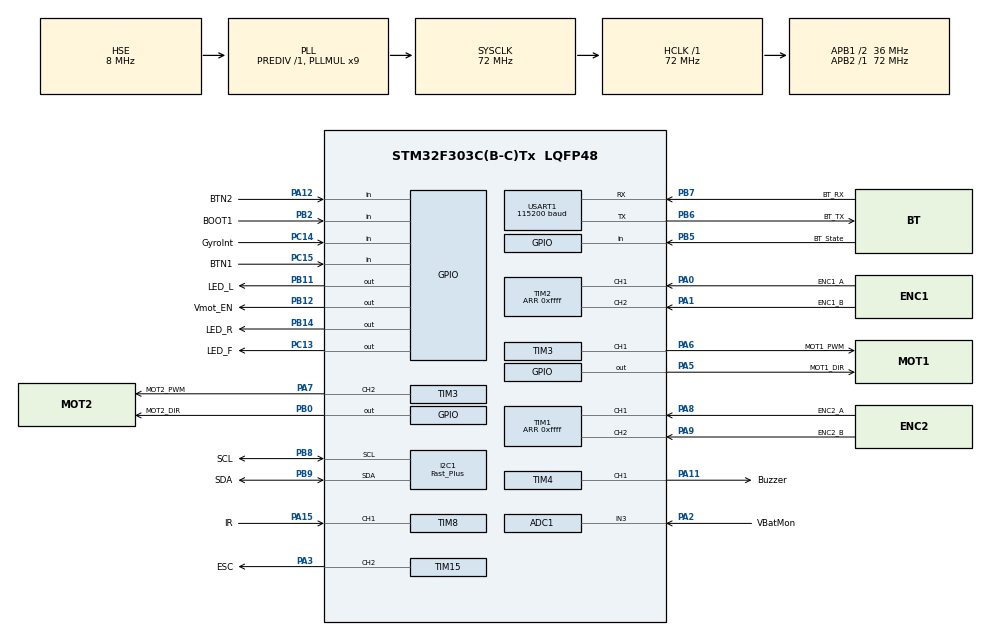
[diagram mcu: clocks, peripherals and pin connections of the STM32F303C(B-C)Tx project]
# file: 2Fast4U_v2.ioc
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ADC1.Channel-0\#ChannelRegularConversion=ADC_CHANNEL_3
ADC1.ClockPrescaler=ADC_CLOCK_ASYNC_DIV1
ADC1.ContinuousConvMode=DISABLE
ADC1.DMAContinuousRequests=DISABLE
ADC1.DataAlign=ADC_DATAALIGN_RIGHT
ADC1.DiscontinuousConvMode=DISABLE
ADC1.EOCSelection=ADC_EOC_SINGLE_CONV
ADC1.EnableAnalogWatchDog1=false
ADC1.EnableAnalogWatchDog2=false
ADC1.EnableAnalogWatchDog3=false
ADC1.EnableInjectedConversion=ENABLE
ADC1.EnableRegularConversion=ENABLE
ADC1.ExternalTrigConv=ADC_SOFTWARE_START
ADC1.ExternalTrigConvEdge=ADC_EXTERNALTRIGCONVEDGE_NONE
ADC1.InjNumberOfConversion=0
ADC1.LowPowerAutoWait=DISABLE
ADC1.NbrOfConversion=1
ADC1.NbrOfConversionFlag=1
ADC1.Offset-0\#ChannelRegularConversion=0
ADC1.OffsetNumber-0\#ChannelRegularConversion=ADC_OFFSET_NONE
ADC1.Overrun=ADC_OVR_DATA_OVERWRITTEN
ADC1.Rank-0\#ChannelRegularConversion=1
ADC1.Resolution=ADC_RESOLUTION_12B
ADC1.SamplingTime-0\#ChannelRegularConversion=ADC_SAMPLETIME_1CYCLE_5
ADC1.ScanConvMode=ADC_SCAN_DISABLE
ADC1.master=1
Dma.I2C1_RX.2.Direction=DMA_PERIPH_TO_MEMORY
Dma.I2C1_RX.2.Instance=DMA1_Channel7
Dma.I2C1_RX.2.MemDataAlignment=DMA_MDATAALIGN_BYTE
Dma.I2C1_RX.2.MemInc=DMA_MINC_ENABLE
Dma.I2C1_RX.2.Mode=DMA_NORMAL
Dma.I2C1_RX.2.PeriphDataAlignment=DMA_PDATAALIGN_BYTE
Dma.I2C1_RX.2.PeriphInc=DMA_PINC_DISABLE
Dma.I2C1_RX.2.Priority=DMA_PRIORITY_HIGH
Dma.Request0=USART1_TX
Dma.Request1=USART1_RX
Dma.Request2=I2C1_RX
Dma.USART1_RX.1.Direction=DMA_PERIPH_TO_MEMORY
Dma.USART1_RX.1.Instance=DMA1_Channel5
Dma.USART1_RX.1.MemDataAlignment=DMA_MDATAALIGN_BYTE
Dma.USART1_RX.1.MemInc=DMA_MINC_ENABLE
Dma.USART1_RX.1.Mode=DMA_CIRCULAR
Dma.USART1_RX.1.PeriphDataAlignment=DMA_PDATAALIGN_BYTE
Dma.USART1_RX.1.PeriphInc=DMA_PINC_DISABLE
Dma.USART1_RX.1.Priority=DMA_PRIORITY_LOW
Dma.USART1_TX.0.Direction=DMA_MEMORY_TO_PERIPH
Dma.USART1_TX.0.Instance=DMA1_Channel4
Dma.USART1_TX.0.MemDataAlignment=DMA_MDATAALIGN_BYTE
Dma.USART1_TX.0.MemInc=DMA_MINC_ENABLE
Dma.USART1_TX.0.Mode=DMA_NORMAL
Dma.USART1_TX.0.PeriphDataAlignment=DMA_PDATAALIGN_BYTE
Dma.USART1_TX.0.PeriphInc=DMA_PINC_DISABLE
Dma.USART1_TX.0.Priority=DMA_PRIORITY_LOW
I2C1.I2C_Speed_Mode=I2C_Fast_Plus
I2C1.Speed=300
I2C1.Timing=0x00000212
Mcu.Family=STM32F3
Mcu.Name=STM32F303C(B-C)Tx
Mcu.Package=LQFP48
NVIC.DMA1_Channel4_IRQn=true\:0\:0\:false\:false\:true\:false
NVIC.DMA1_Channel5_IRQn=true\:0\:0\:false\:false\:true\:false
NVIC.DMA1_Channel7_IRQn=true\:0\:0\:false\:false\:true\:false
NVIC.I2C1_EV_IRQn=true\:0\:0\:false\:false\:true\:true
NVIC.PriorityGroup=NVIC_PRIORITYGROUP_4
NVIC.USART1_IRQn=true\:0\:0\:false\:false\:true\:true
PA0.GPIO_Label=ENC1_A
PA0.Signal=S_TIM2_CH1_ETR
PA1.GPIO_Label=ENC1_B
PA1.Signal=S_TIM2_CH2
PA11.GPIO_Label=Buzzer
PA11.Signal=S_TIM4_CH1
PA12.GPIO_Label=BTN2
PA12.GPIO_PuPd=GPIO_PULLUP
PA12.Signal=GPIO_Input
PA13.GPIO_Label=SWDIO
PA13.Mode=Trace_Asynchronous_SW
PA13.Signal=SYS_JTMS-SWDIO
PA14.GPIO_Label=SWCLK
PA14.Mode=Trace_Asynchronous_SW
PA14.Signal=SYS_JTCK-SWCLK
PA15.GPIO_Label=IR
PA15.GPIO_PuPd=GPIO_PULLUP
PA15.GPIO_Speed=GPIO_SPEED_FREQ_MEDIUM
PA15.Signal=S_TIM8_CH1
PA2.GPIO_Label=VBatMon
PA2.Mode=IN3-Single-Ended
PA2.Signal=ADC1_IN3
PA3.GPIO_Label=ESC
PA3.Signal=S_TIM15_CH2
PA5.GPIO_Label=MOT1_DIR
PA5.Signal=GPIO_Output
PA6.GPIO_Label=MOT1_PWM
PA6.GPIO_Speed=GPIO_SPEED_FREQ_MEDIUM
PA6.Signal=S_TIM3_CH1
PA7.GPIO_Label=MOT2_PWM
PA7.GPIO_Speed=GPIO_SPEED_FREQ_MEDIUM
PA7.Signal=S_TIM3_CH2
PA8.GPIO_Label=ENC2_A
PA8.Signal=S_TIM1_CH1
PA9.GPIO_Label=ENC2_B
PA9.Signal=S_TIM1_CH2
PB0.GPIO_Label=MOT2_DIR
PB0.Signal=GPIO_Output
PB11.GPIO_Label=LED_L
PB11.Signal=GPIO_Output
PB12.GPIO_Label=Vmot_EN
PB12.Signal=GPIO_Output
PB14.GPIO_Label=LED_R
PB14.Signal=GPIO_Output
PB2.GPIO_Label=BOOT1
PB2.Signal=GPIO_Input
PB3.GPIO_Label=SWO
PB3.Mode=Trace_Asynchronous_SW
PB3.Signal=SYS_JTDO-TRACESWO
PB5.GPIO_Label=BT_State
PB5.Signal=GPIO_Input
PB6.GPIO_Label=BT_TX
PB6.Mode=Asynchronous
PB6.Signal=USART1_TX
PB7.GPIO_Label=BT_RX
PB7.Mode=Asynchronous
PB7.Signal=USART1_RX
PB8.GPIO_Label=SCL
PB8.Mode=I2C
PB8.Signal=I2C1_SCL
PB9.GPIO_Label=SDA
PB9.Mode=I2C
PB9.Signal=I2C1_SDA
PC13.GPIO_Label=LED_F
PC13.Signal=GPIO_Output
PC14-OSC32_IN.GPIO_Label=GyroInt
PC14-OSC32_IN.Signal=GPIO_Input
PC15-OSC32_OUT.GPIO_Label=BTN1
PC15-OSC32_OUT.GPIO_PuPd=GPIO_PULLUP
PC15-OSC32_OUT.Signal=GPIO_Input
PF0-OSC_IN.Mode=HSE-External-Oscillator
PF0-OSC_IN.Signal=RCC_OSC_IN
PF1-OSC_OUT.Mode=HSE-External-Oscillator
PF1-OSC_OUT.Signal=RCC_OSC_OUT
ProjectManager.HeapSize=0x200
ProjectManager.StackSize=0x400
ProjectManager.TargetToolchain=SW4STM32
RCC.AHBFreq_Value=72000000
RCC.APB1CLKDivider=RCC_HCLK_DIV2
RCC.APB1Freq_Value=36000000
RCC.APB1TimFreq_Value=72000000
RCC.APB2Freq_Value=72000000
RCC.APB2TimFreq_Value=72000000
RCC.CortexFreq_Value=72000000
RCC.HCLKFreq_Value=72000000
RCC.HSE_VALUE=8000000
RCC.HSI_VALUE=8000000
RCC.LSE_VALUE=32768
RCC.PLLMUL=RCC_PLL_MUL9
RCC.PLLSourceVirtual=RCC_PLLSOURCE_HSE
RCC.SYSCLKFreq_VALUE=72000000
RCC.SYSCLKSourceVirtual=RCC_SYSCLKSOURCE_PLLCLK
RCC.USBFreq_Value=72000000
SH.S_TIM15_CH2.0=TIM15_CH2,PWM Generation2 CH2
SH.S_TIM1_CH1.0=TIM1_CH1,Encoder_Interface
SH.S_TIM1_CH2.0=TIM1_CH2,Encoder_Interface
SH.S_TIM2_CH1_ETR.0=TIM2_CH1,Encoder_Interface
SH.S_TIM2_CH2.0=TIM2_CH2,Encoder_Interface
SH.S_TIM3_CH1.0=TIM3_CH1,PWM Generation1 CH1
SH.S_TIM3_CH2.0=TIM3_CH2,PWM Generation2 CH2
SH.S_TIM4_CH1.0=TIM4_CH1,PWM Generation1 CH1
SH.S_TIM8_CH1.0=TIM8_CH1,Input_Capture1_from_TI1
TIM1.CounterMode=TIM_COUNTERMODE_UP
TIM1.Period=0xffff
TIM15.Channel-PWM\ Generation2\ CH2=TIM_CHANNEL_2
TIM15.Period=1000
TIM15.Pulse-PWM\ Generation2\ CH2=100
TIM2.CounterMode=TIM_COUNTERMODE_UP
TIM2.Period=0xffff
TIM3.Channel-PWM\ Generation1\ CH1=TIM_CHANNEL_1
TIM3.Channel-PWM\ Generation2\ CH2=TIM_CHANNEL_2
TIM3.ClockDivision=TIM_CLOCKDIVISION_DIV1
TIM3.Period=0xFF
TIM3.Prescaler=9
TIM3.Pulse-PWM\ Generation1\ CH1=0
TIM3.Pulse-PWM\ Generation2\ CH2=0
TIM4.Channel-PWM\ Generation1\ CH1=TIM_CHANNEL_1
TIM4.OCMode_PWM-PWM\ Generation1\ CH1=TIM_OCMODE_PWM1
TIM4.Period=100
TIM4.Prescaler=150
TIM4.Pulse-PWM\ Generation1\ CH1=50
TIM8.Channel-Input_Capture1_from_TI1=TIM_CHANNEL_1
USART1.BaudRate=115200
USART1.VirtualMode-Asynchronous=VM_ASYNC
VP_TIM8_VS_ClockSourceITR.Mode=TriggerSource_ITR3
VP_TIM8_VS_ControllerModeReset.Mode=Reset Mode
board=2Fast4U_v2

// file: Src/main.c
/**
  ******************************************************************************
  * File Name          : main.c
  * Description        : Main program body
  ******************************************************************************
  ** This notice applies to any and all portions of this file
  * that are not between comment pairs USER CODE BEGIN and
  * USER CODE END. Other portions of this file, whether
  * inserted by the user or by software development tools
  * are owned by their respective copyright owners.
  *
  * COPYRIGHT(c) 2017 STMicroelectronics
  *
  * Redistribution and use in source and binary forms, with or without modification,
  * are permitted provided that the following conditions are met:
  *   1. Redistributions of source code must retain the above copyright notice,
  *      this list of conditions and the following disclaimer.
  *   2. Redistributions in binary form must reproduce the above copyright notice,
  *      this list of conditions and the following disclaimer in the documentation
  *      and/or other materials provided with the distribution.
  *   3. Neither the name of STMicroelectronics nor the names of its contributors
  *      may be used to endorse or promote products derived from this software
  *      without specific prior written permission.
  *
  * THIS SOFTWARE IS PROVIDED BY THE COPYRIGHT HOLDERS AND CONTRIBUTORS "AS IS"
  * AND ANY EXPRESS OR IMPLIED WARRANTIES, INCLUDING, BUT NOT LIMITED TO, THE
  * IMPLIED WARRANTIES OF MERCHANTABILITY AND FITNESS FOR A PARTICULAR PURPOSE ARE
  * DISCLAIMED. IN NO EVENT SHALL THE COPYRIGHT HOLDER OR CONTRIBUTORS BE LIABLE
  * FOR ANY DIRECT, INDIRECT, INCIDENTAL, SPECIAL, EXEMPLARY, OR CONSEQUENTIAL
  * DAMAGES (INCLUDING, BUT NOT LIMITED TO, PROCUREMENT OF SUBSTITUTE GOODS OR
  * SERVICES; LOSS OF USE, DATA, OR PROFITS; OR BUSINESS INTERRUPTION) HOWEVER
  * CAUSED AND ON ANY THEORY OF LIABILITY, WHETHER IN CONTRACT, STRICT LIABILITY,
  * OR TORT (INCLUDING NEGLIGENCE OR OTHERWISE) ARISING IN ANY WAY OUT OF THE USE
  * OF THIS SOFTWARE, EVEN IF ADVISED OF THE POSSIBILITY OF SUCH DAMAGE.
  *
  ******************************************************************************
  */

#include "main.h"
#include "stm32f3xx_hal.h"
#include "adc.h"
#include "dma.h"
#include "i2c.h"
#include "tim.h"
#include "usart.h"
#include "gpio.h"

/* USER CODE BEGIN Includes */
#ifdef __cplusplus
extern "C" {
#endif
#include "TFFU/TFFUMain.h"
#ifdef __cplusplus
}
#endif
/* USER CODE END Includes */

/* USER CODE BEGIN PV */
/* Private variables ---------------------------------------------------------*/

/* USER CODE END PV */

void SystemClock_Config(void);

/* USER CODE BEGIN PFP */
/* Private function prototypes -----------------------------------------------*/
//extern void initialise_monitor_handles(void);
/* USER CODE END PFP */

int main(void)
{

  /* MCU Configuration----------------------------------------------------------*/

  /* Reset of all peripherals, Initializes the Flash interface and the Systick. */
  HAL_Init();

  /* Configure the system clock */
  SystemClock_Config();

  /* Initialize all configured peripherals */
  MX_GPIO_Init();
  MX_DMA_Init();
  MX_ADC1_Init();
  MX_I2C1_Init();
  MX_TIM1_Init();
  MX_TIM2_Init();
  MX_TIM3_Init();
  MX_TIM4_Init();
  MX_TIM8_Init();
  MX_TIM15_Init();
  MX_USART1_UART_Init();

  /* USER CODE BEGIN 2 */
  //initialise_monitor_handles(); // semihosting
  /* USER CODE END 2 */

  /* Infinite loop */
  /* USER CODE BEGIN WHILE */
  while (1)
  {
	  TFFUMain();
  /* USER CODE END WHILE */

  }

}

/** System Clock Configuration
*/
void SystemClock_Config(void)
{

  RCC_OscInitTypeDef RCC_OscInitStruct;
  RCC_ClkInitTypeDef RCC_ClkInitStruct;
  RCC_PeriphCLKInitTypeDef PeriphClkInit;

    /**Initializes the CPU, AHB and APB busses clocks
    */
  RCC_OscInitStruct.OscillatorType = RCC_OSCILLATORTYPE_HSI|RCC_OSCILLATORTYPE_HSE;
  RCC_OscInitStruct.HSEState = RCC_HSE_ON;
  RCC_OscInitStruct.HSEPredivValue = RCC_HSE_PREDIV_DIV1;
  RCC_OscInitStruct.HSIState = RCC_HSI_ON;
  RCC_OscInitStruct.HSICalibrationValue = 16;
  RCC_OscInitStruct.PLL.PLLState = RCC_PLL_ON;
  RCC_OscInitStruct.PLL.PLLSource = RCC_PLLSOURCE_HSE;
  RCC_OscInitStruct.PLL.PLLMUL = RCC_PLL_MUL9;
  if (HAL_RCC_OscConfig(&RCC_OscInitStruct) != HAL_OK)
  {
    _Error_Handler(__FILE__, __LINE__);
  }

    /**Initializes the CPU, AHB and APB busses clocks
    */
  RCC_ClkInitStruct.ClockType = RCC_CLOCKTYPE_HCLK|RCC_CLOCKTYPE_SYSCLK
                              |RCC_CLOCKTYPE_PCLK1|RCC_CLOCKTYPE_PCLK2;
  RCC_ClkInitStruct.SYSCLKSource = RCC_SYSCLKSOURCE_PLLCLK;
  RCC_ClkInitStruct.AHBCLKDivider = RCC_SYSCLK_DIV1;
  RCC_ClkInitStruct.APB1CLKDivider = RCC_HCLK_DIV2;
  RCC_ClkInitStruct.APB2CLKDivider = RCC_HCLK_DIV1;

  if (HAL_RCC_ClockConfig(&RCC_ClkInitStruct, FLASH_LATENCY_2) != HAL_OK)
  {
    _Error_Handler(__FILE__, __LINE__);
  }

  PeriphClkInit.PeriphClockSelection = RCC_PERIPHCLK_USART1|RCC_PERIPHCLK_I2C1
                              |RCC_PERIPHCLK_TIM1|RCC_PERIPHCLK_TIM8
                              |RCC_PERIPHCLK_ADC12;
  PeriphClkInit.Usart1ClockSelection = RCC_USART1CLKSOURCE_PCLK2;
  PeriphClkInit.Adc12ClockSelection = RCC_ADC12PLLCLK_DIV1;
  PeriphClkInit.I2c1ClockSelection = RCC_I2C1CLKSOURCE_HSI;
  PeriphClkInit.Tim1ClockSelection = RCC_TIM1CLK_HCLK;
  PeriphClkInit.Tim8ClockSelection = RCC_TIM8CLK_HCLK;
  if (HAL_RCCEx_PeriphCLKConfig(&PeriphClkInit) != HAL_OK)
  {
    _Error_Handler(__FILE__, __LINE__);
  }

    /**Configure the Systick interrupt time
    */
  HAL_SYSTICK_Config(HAL_RCC_GetHCLKFreq()/1000);

    /**Configure the Systick
    */
  HAL_SYSTICK_CLKSourceConfig(SYSTICK_CLKSOURCE_HCLK);

  /* SysTick_IRQn interrupt configuration */
  HAL_NVIC_SetPriority(SysTick_IRQn, 0, 0);
}

void _Error_Handler(char * file, int line)
{
  /* USER CODE BEGIN Error_Handler_Debug */
	return;
  /* User can add his own implementation to report the HAL error return state */
  while(1)
  {
  }
  /* USER CODE END Error_Handler_Debug */
}

/************************ (C) COPYRIGHT STMicroelectronics *****END OF FILE****/
